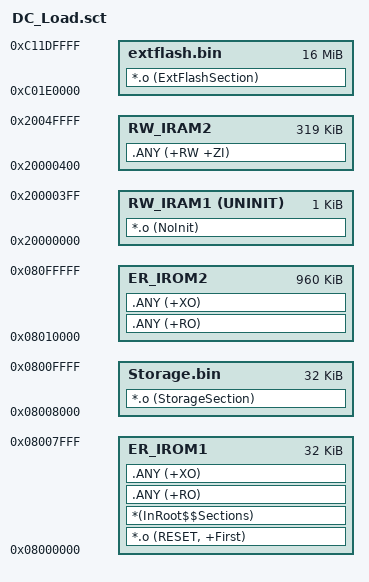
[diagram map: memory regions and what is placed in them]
; *************************************************************
; *** Scatter-Loading Description File generated by uVision ***
; *************************************************************

LR_IROM1 0x08000000 0x00008000  {    ; load region size_region
  ER_IROM1 0x08000000 0x00008000  {  ; load address = execution address
   *.o (RESET, +First)
   *(InRoot$$Sections)
   .ANY (+RO)
   .ANY (+XO)
  }
}

LR_STORAGE 0x08008000 0x00008000  {    ; load region size_region
  Storage.bin 0x08008000 0x00008000 {
	*.o (StorageSection)
  }
}

LR_IROM2 0x08010000 0x000F0000  {    ; load region size_region
  ER_IROM2 0x08010000 0x000F0000  {  ; load address = execution address
   .ANY (+RO)
   .ANY (+XO)
  }
  RW_IRAM1 0x20000000 UNINIT 0x00000400  { ;no init section
    *.o (NoInit)
  }
  RW_IRAM2 0x20000400 0x0004FC00  {  ; RW data
   .ANY (+RW +ZI)
  }
}

LR_EROM1 0xC01E0000 0x01000000 { ; load region size_region
  extflash.bin 0xC01E0000 0x01000000 { ; load address = execution address
    *.o (ExtFlashSection)
;    *.o (FontFlashSection)
;    *.o (TextFlashSection)
  }
}


